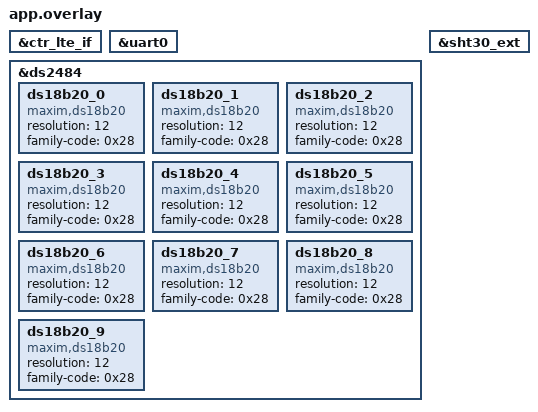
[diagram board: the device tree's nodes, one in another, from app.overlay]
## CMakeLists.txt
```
#
# Copyright (c) 2024 HARDWARIO a.s.
#
# SPDX-License-Identifier: LicenseRef-HARDWARIO-5-Clause
#

cmake_minimum_required(VERSION 3.20.0)

find_package(Zephyr REQUIRED HINTS $ENV{ZEPHYR_BASE})

project(chester-clime)


target_sources(app PRIVATE src/app_shell.c)
target_sources(app PRIVATE src/app_config.c)
```

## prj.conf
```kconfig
#
# Copyright (c) 2023 HARDWARIO a.s.
#
# SPDX-License-Identifier: LicenseRef-HARDWARIO-5-Clause
#

# Configurations ------------------------------------------------------------------ #
CONFIG_CTR_BLE=y
CONFIG_CTR_SHELL=y
CONFIG_CTR_LED=y
CONFIG_CTR_BUTTON=y
CONFIG_CTR_LTE_CLKSYNC=y

# Extra configurations ------------------------------------------------------------------ #
CONFIG_BT=n
CONFIG_APP_INIT_PRIORITY=50

# USER CODE BEGIN Config           
# USER CODE END Config 
```

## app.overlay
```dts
/*
 * Copyright (c) 2023 HARDWARIO a.s.
 *
 * SPDX-License-Identifier: LicenseRef-HARDWARIO-5-Clause
 */


/* Clime 1WH -------------------------------------------------*/

/* ctr_lte ----------------------------------------------------------------------*/
&ctr_lte_if {
	status = "okay";
};

&uart0 {
	status = "okay";
};
                
/* ctr_ds18b20 ----------------------------------------------------------------------*/
&ds2484 {
	ds18b20_0: ds18b20_0 {
		compatible = "maxim,ds18b20";
		resolution = <12>;
		family-code = <0x28>;
	};
	ds18b20_1: ds18b20_1 {
		compatible = "maxim,ds18b20";
		resolution = <12>;
		family-code = <0x28>;
	};
	ds18b20_2: ds18b20_2 {
		compatible = "maxim,ds18b20";
		resolution = <12>;
		family-code = <0x28>;
	};
	ds18b20_3: ds18b20_3 {
		compatible = "maxim,ds18b20";
		resolution = <12>;
		family-code = <0x28>;
	};
	ds18b20_4: ds18b20_4 {
		compatible = "maxim,ds18b20";
		resolution = <12>;
		family-code = <0x28>;
	};
	ds18b20_5: ds18b20_5 {
		compatible = "maxim,ds18b20";
		resolution = <12>;
		family-code = <0x28>;
	};
	ds18b20_6: ds18b20_6 {
		compatible = "maxim,ds18b20";
		resolution = <12>;
		family-code = <0x28>;
	};
	ds18b20_7: ds18b20_7 {
		compatible = "maxim,ds18b20";
		resolution = <12>;
		family-code = <0x28>;
	};
	ds18b20_8: ds18b20_8 {
		compatible = "maxim,ds18b20";
		resolution = <12>;
		family-code = <0x28>;
	};
	ds18b20_9: ds18b20_9 {
		compatible = "maxim,ds18b20";
		resolution = <12>;
		family-code = <0x28>;
	};
};
                
/* ctr_s2 ----------------------------------------------------------------------*/
&sht30_ext {
	status = "okay";
};
                
    

/* USER CODE BEGIN Overlay */
/* USER CODE END Overlay */
```

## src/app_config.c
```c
/*
 * Copyright (c) 2023 HARDWARIO a.s.
 *
 * SPDX-License-Identifier: LicenseRef-HARDWARIO-5-Clause
 */

/* Includes ------------------------------------------------------------------*/

#include "app_config.h"

/* Private includes --------------------------------------------------------------------*/

/* CHESTER includes */
#include <chester/ctr_config.h>

/* Zephyr includes */
#include <zephyr/init.h>
#include <zephyr/kernel.h>
#include <zephyr/logging/log.h>
#include <zephyr/settings/settings.h>
#include <zephyr/shell/shell.h>

/* Standard includes */
#include <ctype.h>
#include <stdbool.h>
#include <stdio.h>
#include <stdlib.h>
#include <string.h>

/* USER CODE BEGIN Includes */
/* USER CODE END Includes */

LOG_MODULE_REGISTER(app_config, LOG_LEVEL_DBG);

#define SETTINGS_PFX "chester-clime"

/* Private Variables -------------------------------------------------------------------*/

struct app_config g_app_config;

static struct app_config m_app_config_interim = {
    .interval_report = 3600,
    .apn = "onomondo",
    .temperature = 24.54,
    .interval_aggreg = 1800,
    .interval_sample = 25,
    .event_report_delay = 1,
    .event_report_rate = 30,
    .backup_report_connected = true,
    .backup_report_disconnected = true,
    .mode = APP_CONFIG_MODE_LTE,

    /* USER CODE BEGIN Struct Variables */
    /* USER CODE END Struct Variables */
};

/* USER CODE BEGIN Variables */
/* USER CODE END Variables */

/* Private Functions -------------------------------------------------------------------*/

static void print_interval_report(const struct shell *shell)
{
    shell_print(shell, "app config interval-report  %d", m_app_config_interim.interval_report);
}

int app_config_cmd_config_interval_report(const struct shell *shell, size_t argc, char **argv)
{
    if (argc == 1) {
        print_interval_report(shell);
        return 0;
    }
    if (argc == 2) {
        size_t len = strlen(argv[1]);
        for (size_t i = 0; i < len; i++) {
            if (!isdigit((int)argv[1][i])) {
                shell_error(shell, "invalid format");
                return -EINVAL;
            }
        }
        long value = strtol(argv[1], NULL, 10);
        if (value < 0 || value > 40000) {
            shell_error(shell, "invalid range");
            return -EINVAL;
        }
        m_app_config_interim.interval_report = (int)value;
        return 0;
    }
    shell_help(shell);
    return -EINVAL;
}

static void print_apn(const struct shell *shell)
{
    shell_print(shell, "lte config apn %.1f", m_app_config_interim.apn);
}
int app_config_cmd_config_apn(const struct shell *shell, size_t argc, char **argv)
{
    if (argc == 1) {
        print_apn(shell);
        return 0;
    }
    if (argc == 2) {
            size_t len = strlen(argv[1]);

            if (len >= sizeof(m_config_interim.apn)) {
                shell_error(shell, "invalid format");
                return -EINVAL;
            }

            for (size_t i = 0; i < len; i++) {
                char c = argv[1][i];
                if (!isalnum((int)c) && c != '-' && c != '.') {
                    shell_error(shell, "invalid format");
                    return -EINVAL;
                }
            }

            strcpy(m_config_interim.apn, argv[1]);
            return 0;
        }
    shell_help(shell);
    return -EINVAL;
}

static void print_temperature(const struct shell *shell)
{
    shell_print(shell, "app config temperature %.1f", m_app_config_interim.temperature);
}

int app_config_cmd_config_temperature(const struct shell *shell, size_t argc, char **argv)
{
    if (argc == 1) {
        print_temperature(shell);
        return 0;
    }
    if (argc == 2) {
        float value;
        int ret = sscanf(argv[1], "%f", &value);
        if (ret != 1) {
            shell_error(shell, "invalid value");
            return -EINVAL;
        }
        if (value <  || value > ) 
        {
            shell_error(shell, "invalid range");
            return -EINVAL;
        }
        m_app_config_interim.temperature = value;
        return 0;
    }
    shell_help(shell);
    return -EINVAL;
}

static void print_interval_aggreg(const struct shell *shell)
{
    shell_print(shell, "app config interval-aggreg  %d", m_app_config_interim.interval_aggreg);
}

int app_config_cmd_config_interval_aggreg(const struct shell *shell, size_t argc, char **argv)
{
    if (argc == 1) {
        print_interval_aggreg(shell);
        return 0;
    }
    if (argc == 2) {
        size_t len = strlen(argv[1]);
        for (size_t i = 0; i < len; i++) {
            if (!isdigit((int)argv[1][i])) {
                shell_error(shell, "invalid format");
                return -EINVAL;
            }
        }
        long value = strtol(argv[1], NULL, 10);
        if (value < 0 || value > 65535) {
            shell_error(shell, "invalid range");
            return -EINVAL;
        }
        m_app_config_interim.interval_aggreg = (int)value;
        return 0;
    }
    shell_help(shell);
    return -EINVAL;
}

static void print_interval_sample(const struct shell *shell)
{
    shell_print(shell, "app config interval-sample  %d", m_app_config_interim.interval_sample);
}

int app_config_cmd_config_interval_sample(const struct shell *shell, size_t argc, char **argv)
{
    if (argc == 1) {
        print_interval_sample(shell);
        return 0;
    }
    if (argc == 2) {
        size_t len = strlen(argv[1]);
        for (size_t i = 0; i < len; i++) {
            if (!isdigit((int)argv[1][i])) {
                shell_error(shell, "invalid format");
                return -EINVAL;
            }
        }
        long value = strtol(argv[1], NULL, 10);
        if (value < 0 || value > 65535) {
            shell_error(shell, "invalid range");
            return -EINVAL;
        }
        m_app_config_interim.interval_sample = (int)value;
        return 0;
    }
    shell_help(shell);
    return -EINVAL;
}

static void print_event_report_delay(const struct shell *shell)
{
    shell_print(shell, "app config event-report-delay  %d", m_app_config_interim.event_report_delay);
}

int app_config_cmd_config_event_report_delay(const struct shell *shell, size_t argc, char **argv)
{
    if (argc == 1) {
        print_event_report_delay(shell);
        return 0;
    }
    if (argc == 2) {
        size_t len = strlen(argv[1]);
        for (size_t i = 0; i < len; i++) {
            if (!isdigit((int)argv[1][i])) {
                shell_error(shell, "invalid format");
                return -EINVAL;
            }
        }
        long value = strtol(argv[1], NULL, 10);
        if (value < 0 || value > 65535) {
            shell_error(shell, "invalid range");
            return -EINVAL;
        }
        m_app_config_interim.event_report_delay = (int)value;
        return 0;
    }
    shell_help(shell);
    return -EINVAL;
}

static void print_event_report_rate(const struct shell *shell)
{
    shell_print(shell, "app config event-report-rate  %d", m_app_config_interim.event_report_rate);
}

int app_config_cmd_config_event_report_rate(const struct shell *shell, size_t argc, char **argv)
{
    if (argc == 1) {
        print_event_report_rate(shell);
        return 0;
    }
    if (argc == 2) {
        size_t len = strlen(argv[1]);
        for (size_t i = 0; i < len; i++) {
            if (!isdigit((int)argv[1][i])) {
                shell_error(shell, "invalid format");
                return -EINVAL;
            }
        }
        long value = strtol(argv[1], NULL, 10);
        if (value < 0 || value > 65535) {
            shell_error(shell, "invalid range");
            return -EINVAL;
        }
        m_app_config_interim.event_report_rate = (int)value;
        return 0;
    }
    shell_help(shell);
    return -EINVAL;
}

static void print_backup_report_connected(const struct shell *shell)
{
    shell_print(shell, "app config backup-report-connected  %s", m_app_config_interim.backup_report_connected ? "true" : "false");
}

int app_config_cmd_config_backup_report_connected(const struct shell *shell, size_t argc, char **argv)
{
    if (argc == 1) {
        print_backup_report_connected(shell);                                                    
        return 0;
    }
    if (argc == 2) {
        bool is_false = !strcmp(argv[1], "false");
        bool is_true = !strcmp(argv[1], "true");
        if (is_false) {
            m_app_config_interim.backup_report_connected = false;
        } else if (is_true) {
            m_app_config_interim.backup_report_connected = true;
        } else {
            shell_error(shell, "invalid format");
            return -EINVAL;
        }
        return 0;
    }
    shell_help(shell);
    return -EINVAL;
}

static void print_backup_report_disconnected(const struct shell *shell)
{
    shell_print(shell, "app config backup-report-disconnected  %s", m_app_config_interim.backup_report_disconnected ? "true" : "false");
}

int app_config_cmd_config_backup_report_disconnected(const struct shell *shell, size_t argc, char **argv)
{
    if (argc == 1) {
        print_backup_report_disconnected(shell);                                                    
        return 0;
    }
    if (argc == 2) {
        bool is_false = !strcmp(argv[1], "false");
        bool is_true = !strcmp(argv[1], "true");
        if (is_false) {
            m_app_config_interim.backup_report_disconnected = false;
        } else if (is_true) {
            m_app_config_interim.backup_report_disconnected = true;
        } else {
            shell_error(shell, "invalid format");
            return -EINVAL;
        }
        return 0;
    }
    shell_help(shell);
    return -EINVAL;
}

int app_config_cmd_config_show(const struct shell *shell, size_t argc, char **argv)
{
	print_interval_report(shell);
	print_apn(shell);
	print_temperature(shell);
	print_interval_aggreg(shell);
	print_interval_sample(shell);
	print_event_report_delay(shell);
	print_event_report_rate(shell);
	print_backup_report_connected(shell);
	print_backup_report_disconnected(shell);
    
    return 0;
}

/* USER CODE BEGIN Functions 1 */
/* USER CODE END Functions 1 */

static int h_commit(void)
{
	LOG_DBG("Loaded settings in full");
	memcpy(&g_app_config, &m_app_config_interim, sizeof(g_app_config));

	return 0;
}

static int h_set(const char *key, size_t len, settings_read_cb read_cb, void *cb_arg) 
{
    int ret;
    const char *next;

    if (settings_name_steq(key, "interval-report", &next) && !next) {
        if (len != sizeof(m_app_config_interim.interval_report)) {
            return -EINVAL;
        }
        ret = read_cb(cb_arg, &m_app_config_interim.interval_report, len);
        if (ret < 0) {
            LOG_ERR("Call `read_cb` failed: %d", ret);
            return ret;
        }
        return 0;
    }
    if (settings_name_steq(key, "apn", &next) && !next) {
        if (len != sizeof(m_app_config_interim.apn)) {
            return -EINVAL;
        }
        ret = read_cb(cb_arg, &m_app_config_interim.apn, len);
        if (ret < 0) {
            LOG_ERR("Call `read_cb` failed: %d", ret);
            return ret;
        }
        return 0;
    }
    if (settings_name_steq(key, "temperature", &next) && !next) {
        if (len != sizeof(m_app_config_interim.temperature)) {
            return -EINVAL;
        }
        ret = read_cb(cb_arg, &m_app_config_interim.temperature, len);
        if (ret < 0) {
            LOG_ERR("Call `read_cb` failed: %d", ret);
            return ret;
        }
        return 0;
    }
    if (settings_name_steq(key, "interval-aggreg", &next) && !next) {
        if (len != sizeof(m_app_config_interim.interval_aggreg)) {
            return -EINVAL;
        }
        ret = read_cb(cb_arg, &m_app_config_interim.interval_aggreg, len);
        if (ret < 0) {
            LOG_ERR("Call `read_cb` failed: %d", ret);
            return ret;
        }
        return 0;
    }
    if (settings_name_steq(key, "interval-sample", &next) && !next) {
        if (len != sizeof(m_app_config_interim.interval_sample)) {
            return -EINVAL;
        }
        ret = read_cb(cb_arg, &m_app_config_interim.interval_sample, len);
        if (ret < 0) {
            LOG_ERR("Call `read_cb` failed: %d", ret);
            return ret;
        }
        return 0;
    }
    if (settings_name_steq(key, "event-report-delay", &next) && !next) {
        if (len != sizeof(m_app_config_interim.event_report_delay)) {
            return -EINVAL;
        }
        ret = read_cb(cb_arg, &m_app_config_interim.event_report_delay, len);
        if (ret < 0) {
            LOG_ERR("Call `read_cb` failed: %d", ret);
            return ret;
        }
        return 0;
    }
    if (settings_name_steq(key, "event-report-rate", &next) && !next) {
        if (len != sizeof(m_app_config_interim.event_report_rate)) {
            return -EINVAL;
        }
        ret = read_cb(cb_arg, &m_app_config_interim.event_report_rate, len);
        if (ret < 0) {
            LOG_ERR("Call `read_cb` failed: %d", ret);
            return ret;
        }
        return 0;
    }
    if (settings_name_steq(key, "backup-report-connected", &next) && !next) {
        if (len != sizeof(m_app_config_interim.backup_report_connected)) {
            return -EINVAL;
        }
        ret = read_cb(cb_arg, &m_app_config_interim.backup_report_connected, len);
        if (ret < 0) {
            LOG_ERR("Call `read_cb` failed: %d", ret);
            return ret;
        }
        return 0;
    }
    if (settings_name_steq(key, "backup-report-disconnected", &next) && !next) {
        if (len != sizeof(m_app_config_interim.backup_report_disconnected)) {
            return -EINVAL;
        }
        ret = read_cb(cb_arg, &m_app_config_interim.backup_report_disconnected, len);
        if (ret < 0) {
            LOG_ERR("Call `read_cb` failed: %d", ret);
            return ret;
        }
        return 0;
    }

    /* USER CODE BEGIN Functions 2 */
    /* USER CODE END Functions 2 */

    return 0;
}

static int h_export(int (*export_func)(const char *name, const void *val, size_t val_len))
{
    int ret;
    ret = export_func("chester-clime/interval-report", &m_app_config_interim.interval_report,
                      sizeof( m_app_config_interim.interval_report));
    if (ret < 0) {
        return ret;
    }

    ret = export_func("chester-clime/apn", &m_app_config_interim.apn,
                      sizeof( m_app_config_interim.apn));
    if (ret < 0) {
        return ret;
    }

    ret = export_func("chester-clime/temperature", &m_app_config_interim.temperature,
                      sizeof( m_app_config_interim.temperature));
    if (ret < 0) {
        return ret;
    }

    ret = export_func("chester-clime/interval-aggreg", &m_app_config_interim.interval_aggreg,
                      sizeof( m_app_config_interim.interval_aggreg));
    if (ret < 0) {
        return ret;
    }

    ret = export_func("chester-clime/interval-sample", &m_app_config_interim.interval_sample,
                      sizeof( m_app_config_interim.interval_sample));
    if (ret < 0) {
        return ret;
    }

    ret = export_func("chester-clime/event-report-delay", &m_app_config_interim.event_report_delay,
                      sizeof( m_app_config_interim.event_report_delay));
    if (ret < 0) {
        return ret;
    }

    ret = export_func("chester-clime/event-report-rate", &m_app_config_interim.event_report_rate,
                      sizeof( m_app_config_interim.event_report_rate));
    if (ret < 0) {
        return ret;
    }

    ret = export_func("chester-clime/backup-report-connected", &m_app_config_interim.backup_report_connected,
                      sizeof( m_app_config_interim.backup_report_connected));
    if (ret < 0) {
        return ret;
    }

    ret = export_func("chester-clime/backup-report-disconnected", &m_app_config_interim.backup_report_disconnected,
                      sizeof( m_app_config_interim.backup_report_disconnected));
    if (ret < 0) {
        return ret;
    }

    /* USER CODE BEGIN Functions 3 */
    /* USER CODE END Functions 3 */

    return 0;
}

static int init(void) 
{
    int ret;

    LOG_INF("System initialization");

    static struct settings_handler sh = {
        .name = SETTINGS_PFX,
        .h_set = h_set,
        .h_commit = h_commit,
        .h_export = h_export,
    };

    ret = settings_register(&sh);

    if (ret < 0) {
        LOG_ERR("Call `settings_register` failed: %d", ret);
        return ret;
    }

    ret = settings_load_subtree(SETTINGS_PFX);

    if (ret < 0) {
        LOG_ERR("Call `settings_load_subtree` failed: %d", ret);
        return ret;
    }

    ctr_config_append_show(SETTINGS_PFX, app_config_cmd_config_show);

    /* USER CODE BEGIN Functions 4 */
    /* USER CODE END Functions 4 */

    return 0;
}

SYS_INIT(init, APPLICATION, CONFIG_APPLICATION_INIT_PRIORITY);
```

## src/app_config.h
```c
/*
 * Copyright (c) 2023 HARDWARIO a.s.
 *
 * SPDX-License-Identifier: LicenseRef-HARDWARIO-5-Clause
 */

#ifndef APP_CONFIG_H_
#define APP_CONFIG_H_

/* Includes ------------------------------------------------------------------*/

/* Private includes --------------------------------------------------------------------*/

/* Zephyr includes */
#include <zephyr/shell/shell.h>

/* Standard includes */
#include <stdbool.h>
#include <stddef.h>

/* USER CODE BEGIN Includes */
/* USER CODE END Includes */

#ifdef __cplusplus
extern "C" {
#endif

/* Private Variables -------------------------------------------------------------------*/

enum app_config_mode {
	APP_CONFIG_MODE_NONE = 0,
	APP_CONFIG_MODE_LTE = 1,
	APP_CONFIG_MODE_LRW = 2,
};

struct app_config {
    int interval_report;
    char apn [63 + 1];
    float temperature;
    int interval_aggreg;
    int interval_sample;
    int event_report_delay;
    int event_report_rate;
    bool backup_report_connected;
    bool backup_report_disconnected;

    /* USER CODE BEGIN Struct Variables */
    /* USER CODE END Struct Variables */
};

extern struct app_config g_app_config;

/* USER CODE BEGIN Variables */
/* USER CODE END Variables */

/* Private Functions -------------------------------------------------------------------*/

int app_config_cmd_config_show(const struct shell *shell, size_t argc, char **argv);
int app_config_cmd_config_interval_report(const struct shell *shell, size_t argc, char **argv);
int app_config_cmd_config_temperature(const struct shell *shell, size_t argc, char **argv);
int app_config_cmd_config_interval_aggreg(const struct shell *shell, size_t argc, char **argv);
int app_config_cmd_config_interval_sample(const struct shell *shell, size_t argc, char **argv);
int app_config_cmd_config_event_report_delay(const struct shell *shell, size_t argc, char **argv);
int app_config_cmd_config_event_report_rate(const struct shell *shell, size_t argc, char **argv);
int app_config_cmd_config_backup_report_connected(const struct shell *shell, size_t argc, char **argv);
int app_config_cmd_config_backup_report_disconnected(const struct shell *shell, size_t argc, char **argv);

/* USER CODE BEGIN Functions 1 */
/* USER CODE END Functions 1 */

#ifdef __cplusplus
}
#endif

#endif /* APP_CONFIG_H_ */
```

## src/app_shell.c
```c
/*
 * Copyright (c) 2023 HARDWARIO a.s.
 *
 * SPDX-License-Identifier: LicenseRef-HARDWARIO-5-Clause
 */
 
/* Includes ------------------------------------------------------------------*/

#include "app_config.h"

/* Private includes --------------------------------------------------------------------*/

/* Zephyr includes */
#include <zephyr/kernel.h>
#include <zephyr/logging/log.h>
#include <zephyr/shell/shell.h>

/* Standard includes */
#include <errno.h>
#include <stdlib.h>

/* USER CODE BEGIN Includes */
/* USER CODE END Includes */

LOG_MODULE_REGISTER(app_shell, LOG_LEVEL_INF);

/* USER CODE BEGIN Variables */
/* USER CODE END Variables */

static int print_help(const struct shell *shell, size_t argc, char **argv)
{
    if (argc > 1) {
        shell_error(shell, "command not found: %s", argv[1]);
        shell_help(shell);
        return -EINVAL;
    }

    shell_help(shell);
    return 0;
}

/* clang-format off */

SHELL_STATIC_SUBCMD_SET_CREATE(
    sub_app_config,
   
    SHELL_CMD_ARG(show, NULL,
                  "List current configuration.",
                  app_config_cmd_config_show, 1, 0),

    SHELL_CMD_ARG(interval-report, NULL,
                  "Set report interval (default: 3600)",
                  app_config_cmd_config_interval_report, 1, 1),

    SHELL_CMD_ARG(apn, NULL,
                  "Set APN network name",
                  app_config_cmd_config_apn, 1, 1),

    SHELL_CMD_ARG(temperature, NULL,
                  "Set Temperature 0.0f to 50.f",
                  app_config_cmd_config_temperature, 1, 1),

    SHELL_CMD_ARG(interval-aggreg, NULL,
                  "Set interval aggreg (default: 25)",
                  app_config_cmd_config_interval_aggreg, 1, 1),

    SHELL_CMD_ARG(interval-sample, NULL,
                  "Set interval aggreg (default: 25)",
                  app_config_cmd_config_interval_sample, 1, 1),

    SHELL_CMD_ARG(event-report-delay, NULL,
                  "Set event report delay (default: 1)",
                  app_config_cmd_config_event_report_delay, 1, 1),

    SHELL_CMD_ARG(event-report-rate, NULL,
                  "Set event report rate (default: 30)",
                  app_config_cmd_config_event_report_rate, 1, 1),

    SHELL_CMD_ARG(backup-report-connected, NULL,
                  "Set backup report connected (default: true)",
                  app_config_cmd_config_backup_report_connected, 1, 1),

    SHELL_CMD_ARG(backup-report-disconnected, NULL,
                  "Set backup report disconnected (default: true)",
                  app_config_cmd_config_backup_report_disconnected, 1, 1),

/* USER CODE BEGIN Functions 1 */
/* USER CODE END Functions 1 */

    SHELL_SUBCMD_SET_END
);

SHELL_STATIC_SUBCMD_SET_CREATE(
    sub_app,

    SHELL_CMD_ARG(config, &sub_app_config, "Configuration commands.",
                  print_help, 1, 0),
        
    SHELL_SUBCMD_SET_END

/* USER CODE BEGIN Functions 2 */
/* USER CODE END Functions 2 */

);

SHELL_CMD_REGISTER(app, &sub_app, "Application commands.", print_help);

SHELL_CMD_REGISTER(send, NULL,"Set report interval (default: 3600)",app_send, 1, 1);

/* USER CODE BEGIN Functions 3 */
/* USER CODE END Functions 3 */

/* clang-format on */
```
